# ASR6601 register map
Vendor: ASR Microelectronics; Series: ASR6601; File version: 1
CPU: CM4 r0p1, little endian, no MPU, FPU, 3 interrupt priority bits
Registers are 32-bit, read-write, reset 0x0 unless marked. A register's access mark holds for its fields unless they carry their own. Offsets are from the block's base; [hi:lo] are bit positions; {n}, {i} and the like mark numbered series; 'fields as' and 'values as' point back to an identical list.

## LORAC — LORA Controller
Base 0x40009000
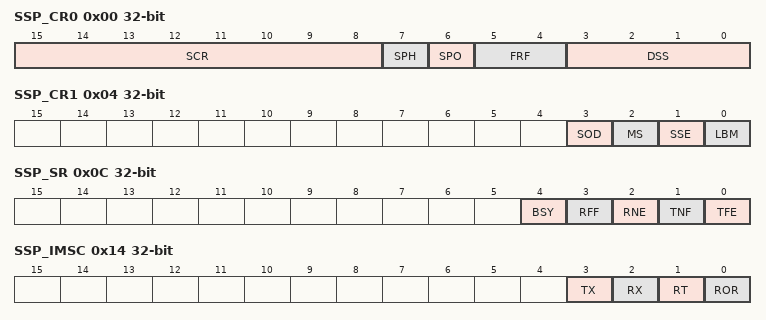
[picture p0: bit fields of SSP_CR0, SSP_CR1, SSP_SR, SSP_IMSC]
0x00 SSP_CR0 — SSP control register 0
  [15:8] SCR — Serial clock rate
  [7] SPH — Serial clock phase
    0=1EDGE (Data is captured on the first clock edge transition); 1=2EDGE (Data is captured on the second clock edge transition)
  [6] SPO — Serial clock polarity
    0=LOW (A steady state LOW value on the clock pin); 1=HIGH (A steady state HIGH value on the clock pin)
  [5:4] FRF — Frame format
    0=SPI (Motorola SPI frame format); 1=TI (TI synchronous serial frame format); 2=MW (National Microwire frame format)
  [3:0] DSS — Data size select
    {v}={v+1}BIT ({v+1}-bit data) (v=3..15)
0x04 SSP_CR1 — SSP control register 1
  [3] SOD — Slave-mode output disable
    0=EN (SSP can drive the TXD output in slave mode); 1=DIS (SSP must not drive the TXD output in slave mode)
  [2] MS — Master or slave mode select
    0=MASTER (Device configured as master); 1=SLAVE (Device configured as slave)
  [1] SSE — SSP enable
    0=DIS (SSP disable); 1=EN (SSP enable)
  [0] LBM — Loop back mode
    0=DIS (Normal serial port operation enabled); 1=EN (Output of transmit serial shifter is connected to input of receive serial shifter internally)
0x08 SSP_DR — SSP data register
0x0C SSP_SR ro — SSP status register
  [4] BSY — SSP busy flag
    0=CLR_FLAG (SSP is idle); 1=SET_FLAG (SSP is currently transmitting and/or receiving a frame or the transmit FIFO is not empty)
  [3] RFF — Receive FIFO full
    0=CLR_FLAG (Receive FIFO is not full); 1=SET_FLAG (Receive FIFO is full)
  [2] RNE — Receive FIFO not empty
    0=CLR_FLAG (Receive FIFO is empty); 1=SET_FLAG (Receive FIFO is not empty)
  [1] TNF — Transmit FIFO not full
    0=CLR_FLAG (Transmit FIFO is full); 1=SET_FLAG (Transmit FIFO is not full)
  [0] TFE — Transmit FIFO empty
    0=CLR_FLAG (Transmit FIFO is not empty); 1=SET_FLAG (Transmit FIFO is empty)
0x10 SSP_CPSR — SSP clock prescale register
  [7:0] CPSDVSR — Clock prescale divisor. Must be an even number between 2-254
0x14 SSP_IMSC — SSP interrupt mask set or clear register
  [3] TX — Transmit FIFO interrupt mask
    0=CLR_FLAG (Transmit FIFO half empty or less condition interrupt is masked); 1=SET_FLAG (Transmit FIFO half empty or less condition interrupt is not masked)
  [2] RX — Receive FIFO interrupt mask
    0=CLR_FLAG (Receive FIFO half full or less condition interrupt is masked); 1=SET_FLAG (Receive FIFO half full or less condition interrupt is not masked)
  [1] RT — Receive timeout interrupt mask
    0=CLR_FLAG (Receive FIFO not empty and no read prior to timeout period interrupt is masked); 1=SET_FLAG (Receive FIFO not empty and no read prior to timeout period interrupt is not masked)
  [0] ROR — Receive overrun interrupt mask
    0=CLR_FLAG (Receive FIFO written to while full condition interrupt is masked); 1=SET_FLAG (Receive FIFO written to while full condition interrupt is not masked)
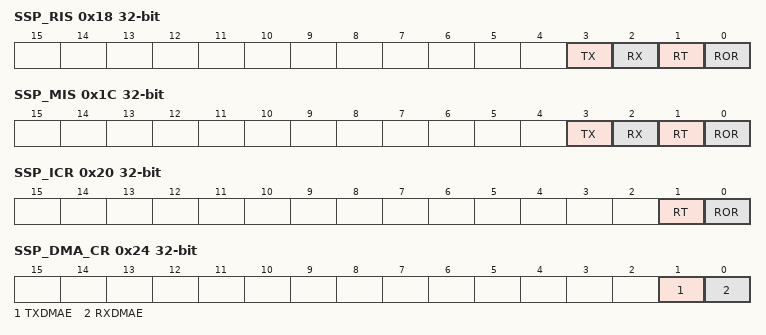
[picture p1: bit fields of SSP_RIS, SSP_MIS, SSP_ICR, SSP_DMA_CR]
0x18 SSP_RIS ro — SSP raw interrupt status register
  [3] TX — Transmit FIFO interrupt status
    0=CLR_FLAG (Interrupt not triggered: Transmit FIFO half empty or less); 1=SET_FLAG (Interrupt triggered: Transmit FIFO half empty or less)
  [2] RX — Receive FIFO interrupt status
    0=CLR_FLAG (Interrupt not triggered: Receive FIFO half full or less); 1=SET_FLAG (Interrupt triggered: Receive FIFO half full or less)
  [1] RT — Receive timeout interrupt status
    0=CLR_FLAG (Interrupt not triggered: Receive FIFO not empty and no read prior to timeout period); 1=SET_FLAG (Interrupt triggered: Receive FIFO not empty and no read prior to timeout period)
  [0] ROR — Receive overrun interrupt status
    0=CLR_FLAG (Interrupt not triggered: Receive FIFO written to while full condition); 1=SET_FLAG (Interrupt triggered: Receive FIFO written to while full condition)
0x1C SSP_MIS ro — SSP masked interrupt status register
  [3] TX — Transmit FIFO masked interrupt status
    values as SSP_RIS.TX
  [2] RX — Receive FIFO masked interrupt status
    values as SSP_RIS.RX
  [1] RT — Receive timeout masked interrupt status
    values as SSP_RIS.RT
  [0] ROR — Receive overrun masked interrupt status
    values as SSP_RIS.ROR
0x20 SSP_ICR — SSP interrupt clear register
  [1] RT — Receive timeout interrupt clear
    0=CLR_FLAG (No effect); 1=SET_FLAG (Clear interrupt: Receive FIFO not empty and no read prior to timeout period)
  [0] ROR — Receive overrun interrupt clear
    0=CLR_FLAG (No effect); 1=SET_FLAG (Clear interrupt: Receive FIFO written to while full condition)
0x24 SSP_DMA_CR — SSP DMA control register
  [1] TXDMAE — Transmit DMA enable
    0=DIS (Transmit DMA disable); 1=EN (Transmit DMA enable)
  [0] RXDMAE — Receive DMA enable
    0=DIS (Receive DMA disable); 1=EN (Receive DMA enable)
0x100 CR0 — Control register 0
0x104 CR1 — Control register 1
0x108 SR ro — Status register
0x10C NSS_CR — NSS control register
0x110 SCK_CR — SCK control register
0x114 MOSI_CR — MOSI control register
0x118 MISO_CR — MISO control register
